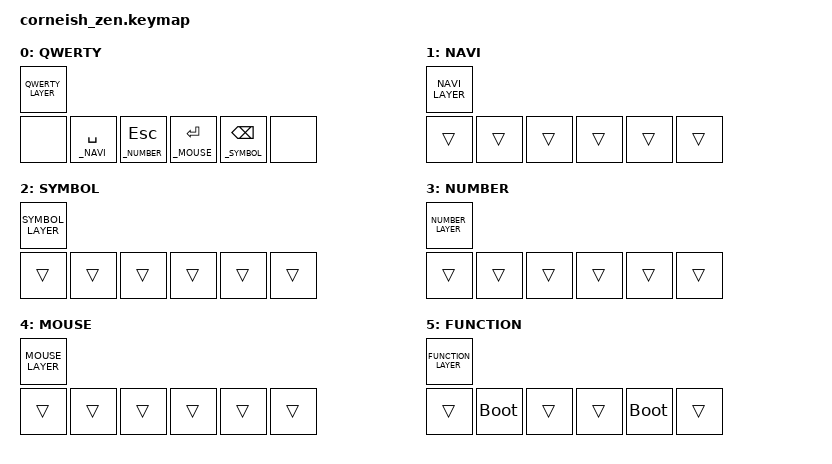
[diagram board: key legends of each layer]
#include <behaviors.dtsi>
#include <dt-bindings/zmk/keys.h>
#include <dt-bindings/zmk/bt.h>
#include <dt-bindings/zmk/matrix_transform.h>
#include <dt-bindings/zmk/outputs.h>
#include <dt-bindings/zmk/pointing.h>
#include "shared.dtsi"

/* Key index
 0  1  2  3  4         5  6  7  8  9
10 11 12 13 14        15 16 17 18 19
20 21 22 23 24        25 26 27 28 29
        30 31 32    33 34 35         */

/ {
  chosen {
    zmk,matrix_transform = &five_column_transform;
  };

  keymap {
    compatible = "zmk,keymap";

    qwerty_layer {
      label = "QWERTY";
      bindings = <
QWERTY_LAYER
&none     &lt _NAVI SPACE &lt _NUMBER ESC    &lt _MOUSE RET  &lt _SYMBOL BSPC   &none
      >;
    };

    navi_layer {
      label = "NAVI";
      bindings = <
NAVI_LAYER
&trans  &trans  &trans    &trans  &trans  &trans
      >;
    };

    symbol_layer {
      label = "SYMBOL";
      bindings = <
SYMBOL_LAYER
&trans  &trans  &trans    &trans  &trans  &trans
      >;
    };

    number_layer {
      label = "NUMBER";
      bindings = <
NUMBER_LAYER
&trans  &trans  &trans    &trans  &trans  &trans
      >;
    };

    mouse_layer {
      label = "MOUSE";
      bindings = <
MOUSE_LAYER
&trans    &trans      &trans       &trans    &trans     &trans
      >;
    };

    function_layer {
      label = "FUNCTION";
      bindings = <
FUNCTION_LAYER
&trans     &bootloader      &trans    &trans  &bootloader     &trans
      >;
    };
  };
};

/* vim: set ft=c tw=174: */
